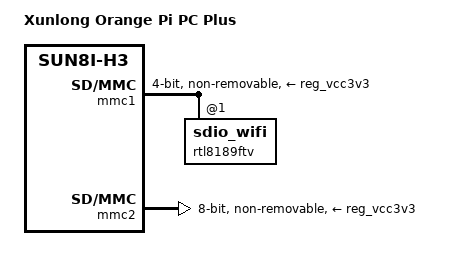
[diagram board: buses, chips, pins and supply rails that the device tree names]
#include "sun8i-h3-orangepi-pc.dts"
/ {
	model = "Xunlong Orange Pi PC Plus";
	compatible = "xunlong,orangepi-pc-plus", "allwinner,sun8i-h3";
	aliases {
		ethernet1 = &rtl8189ftv;
	};
};
&mmc1 {
	vmmc-supply = <&reg_vcc3v3>;
	bus-width = <4>;
	non-removable;
	status = "okay";
	rtl8189ftv: sdio_wifi@1 {
		reg = <1>;
	};
};
&mmc2 {
	pinctrl-names = "default";
	pinctrl-0 = <&mmc2_8bit_pins>;
	vmmc-supply = <&reg_vcc3v3>;
	bus-width = <8>;
	non-removable;
	cap-mmc-hw-reset;
	status = "okay";
};
&mmc2_8bit_pins {
	drive-strength = <40>;
	bias-pull-up;
};
